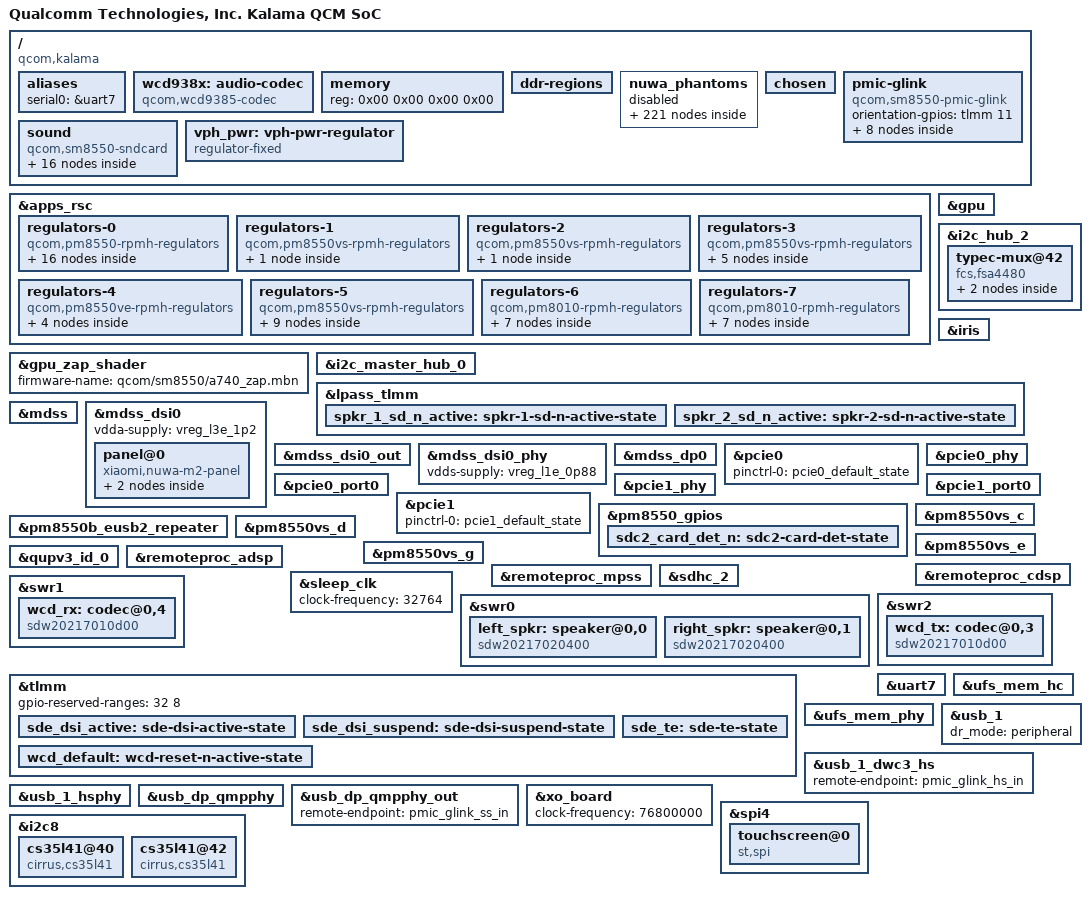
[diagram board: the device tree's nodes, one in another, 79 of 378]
// SPDX-License-Identifier: BSD-3-Clause
/*
 * Copyright (c) 2022, Linaro Limited
 */

/dts-v1/;

#include <dt-bindings/regulator/qcom,rpmh-regulator.h>
#include "sm8550.dtsi"
#include "pm8010.dtsi"
#include "pm8550.dtsi"
#include "pm8550b.dtsi"
#define PMK8550VE_SID 5
#include "pm8550ve.dtsi"
#include "pm8550vs.dtsi"
#include "pmk8550.dtsi"
#include "pmr735d_a.dtsi"
#include "pmr735d_b.dtsi"

/ {
	model = "Qualcomm Technologies, Inc. Kalama QCM SoC";
	compatible = "qcom,kalama";
	qcom,msm-id = <0x25c 0x20000>;
	qcom,board-id = <0x00 0x00>;
	chassis-type = "handset";

	aliases {
		serial0 = &uart7;
	};

	wcd938x: audio-codec {
		compatible = "qcom,wcd9385-codec";

		pinctrl-names = "default";
		pinctrl-0 = <&wcd_default>;

		qcom,micbias1-microvolt = <1800000>;
		qcom,micbias2-microvolt = <1800000>;
		qcom,micbias3-microvolt = <1800000>;
		qcom,micbias4-microvolt = <1800000>;
		qcom,mbhc-buttons-vthreshold-microvolt = <75000 150000 237000 500000 500000 500000 500000 500000>;
		qcom,mbhc-headset-vthreshold-microvolt = <1700000>;
		qcom,mbhc-headphone-vthreshold-microvolt = <50000>;
		qcom,rx-device = <&wcd_rx>;
		qcom,tx-device = <&wcd_tx>;

		reset-gpios = <&tlmm 108 GPIO_ACTIVE_LOW>;

		vdd-buck-supply = <&vreg_l15b_1p8>;
		vdd-rxtx-supply = <&vreg_l15b_1p8>;
		vdd-io-supply = <&vreg_l15b_1p8>;
		vdd-mic-bias-supply = <&vreg_bob1>;

		#sound-dai-cells = <1>;
	};

	memory {
		device_type = "memory";
		reg = <0x00 0x00 0x00 0x00>;
	};

	ddr-regions {
	};

		nuwa_phantoms {
		status = "disabled";
		APC1_pause: sym_APC1_pause { status = "disabled"; };
		APSS_OFF: sym_APSS_OFF { status = "disabled"; };
		BOB1: sym_BOB1 { status = "disabled"; };
		BOB2: sym_BOB2 { status = "disabled"; };
		CLUSTER_PWR_DN: sym_CLUSTER_PWR_DN { status = "disabled"; };
		GOLD_OFF: sym_GOLD_OFF { status = "disabled"; };
		L10B: sym_L10B { status = "disabled"; };
		L11B: sym_L11B { status = "disabled"; };
		L12B: sym_L12B { status = "disabled"; };
		L13B: sym_L13B { status = "disabled"; };
		L14B: sym_L14B { status = "disabled"; };
		L15B: sym_L15B { status = "disabled"; };
		L16B: sym_L16B { status = "disabled"; };
		L17B: sym_L17B { status = "disabled"; };
		L1B: sym_L1B { status = "disabled"; };
		L1C: sym_L1C { status = "disabled"; };
		L1D: sym_L1D { status = "disabled"; };
		L1E: sym_L1E { status = "disabled"; };
		L1F: sym_L1F { status = "disabled"; };
		L1G: sym_L1G { status = "disabled"; };
		L1K: sym_L1K { status = "disabled"; };
		L1M: sym_L1M { status = "disabled"; };
		L1N: sym_L1N { status = "disabled"; };
		L2B: sym_L2B { status = "disabled"; };
		L2C: sym_L2C { status = "disabled"; };
		L2D_LEVEL: sym_L2D_LEVEL { status = "disabled"; };
		L2E: sym_L2E { status = "disabled"; };
		L2F: sym_L2F { status = "disabled"; };
		L2G: sym_L2G { status = "disabled"; };
		L2K: sym_L2K { status = "disabled"; };
		L2M: sym_L2M { status = "disabled"; };
		L2N: sym_L2N { status = "disabled"; };
		L3C: sym_L3C { status = "disabled"; };
		L3E: sym_L3E { status = "disabled"; };
		L3F: sym_L3F { status = "disabled"; };
		L3G: sym_L3G { status = "disabled"; };
		L3K: sym_L3K { status = "disabled"; };
		L3L: sym_L3L { status = "disabled"; };
		L3M: sym_L3M { status = "disabled"; };
		L3N: sym_L3N { status = "disabled"; };
		L4K: sym_L4K { status = "disabled"; };
		L4L: sym_L4L { status = "disabled"; };
		L4M: sym_L4M { status = "disabled"; };
		L4N: sym_L4N { status = "disabled"; };
		L5B: sym_L5B { status = "disabled"; };
		L5K: sym_L5K { status = "disabled"; };
		L5L: sym_L5L { status = "disabled"; };
		L5M: sym_L5M { status = "disabled"; };
		L5N: sym_L5N { status = "disabled"; };
		L6B: sym_L6B { status = "disabled"; };
		L6K: sym_L6K { status = "disabled"; };
		L6L: sym_L6L { status = "disabled"; };
		L6M: sym_L6M { status = "disabled"; };
		L6N: sym_L6N { status = "disabled"; };
		L7B: sym_L7B { status = "disabled"; };
		L7K: sym_L7K { status = "disabled"; };
		L7L: sym_L7L { status = "disabled"; };
		L7M: sym_L7M { status = "disabled"; };
		L7N: sym_L7N { status = "disabled"; };
		L8B: sym_L8B { status = "disabled"; };
		L9B: sym_L9B { status = "disabled"; };
		S3G: sym_S3G { status = "disabled"; };
		S4G: sym_S4G { status = "disabled"; };
		S6G: sym_S6G { status = "disabled"; };
		SILVER_OFF: sym_SILVER_OFF { status = "disabled"; };
		VDD_MMCX_LEVEL: sym_VDD_MMCX_LEVEL { status = "disabled"; };
		VDD_MXA_LEVEL: sym_VDD_MXA_LEVEL { status = "disabled"; };
		altmode: sym_altmode { status = "disabled"; };
		ap2mdm_active: sym_ap2mdm_active { status = "disabled"; };
		ap2mdm_sleep: sym_ap2mdm_sleep { status = "disabled"; };
		apps_rsc_drv2: sym_apps_rsc_drv2 { status = "disabled"; };
		arch_timer: sym_arch_timer { status = "disabled"; };
		audio_gpr: sym_audio_gpr { status = "disabled"; };
		battery_charger: sym_battery_charger { status = "disabled"; };
		bwmon_ddr: sym_bwmon_ddr { status = "disabled"; };
		bwmon_llcc: sym_bwmon_llcc { status = "disabled"; };
		cam_cc_titan_top_gdsc: sym_cam_cc_titan_top_gdsc { status = "disabled"; };
		cam_cci0: sym_cam_cci0 { status = "disabled"; };
		cam_cci1: sym_cam_cci1 { status = "disabled"; };
		cam_cci2: sym_cam_cci2 { status = "disabled"; };
		cam_csiphy0: sym_cam_csiphy0 { status = "disabled"; };
		cam_csiphy1: sym_cam_csiphy1 { status = "disabled"; };
		cam_csiphy2: sym_cam_csiphy2 { status = "disabled"; };
		cam_csiphy3: sym_cam_csiphy3 { status = "disabled"; };
		cam_csiphy4: sym_cam_csiphy4 { status = "disabled"; };
		cam_csiphy5: sym_cam_csiphy5 { status = "disabled"; };
		cam_sensor_active_rst0: sym_cam_sensor_active_rst0 { status = "disabled"; };
		cam_sensor_active_rst1: sym_cam_sensor_active_rst1 { status = "disabled"; };
		cam_sensor_active_rst2: sym_cam_sensor_active_rst2 { status = "disabled"; };
		cam_sensor_active_rst3: sym_cam_sensor_active_rst3 { status = "disabled"; };
		cam_sensor_active_rst4: sym_cam_sensor_active_rst4 { status = "disabled"; };
		cam_sensor_active_rst5: sym_cam_sensor_active_rst5 { status = "disabled"; };
		cam_sensor_mclk0_active: sym_cam_sensor_mclk0_active { status = "disabled"; };
		cam_sensor_mclk0_suspend: sym_cam_sensor_mclk0_suspend { status = "disabled"; };
		cam_sensor_mclk1_active: sym_cam_sensor_mclk1_active { status = "disabled"; };
		cam_sensor_mclk1_suspend: sym_cam_sensor_mclk1_suspend { status = "disabled"; };
		cam_sensor_mclk2_active: sym_cam_sensor_mclk2_active { status = "disabled"; };
		cam_sensor_mclk2_suspend: sym_cam_sensor_mclk2_suspend { status = "disabled"; };
		cam_sensor_mclk3_active: sym_cam_sensor_mclk3_active { status = "disabled"; };
		cam_sensor_mclk3_suspend: sym_cam_sensor_mclk3_suspend { status = "disabled"; };
		cam_sensor_mclk4_active: sym_cam_sensor_mclk4_active { status = "disabled"; };
		cam_sensor_mclk4_suspend: sym_cam_sensor_mclk4_suspend { status = "disabled"; };
		cam_sensor_mclk5_active: sym_cam_sensor_mclk5_active { status = "disabled"; };
		cam_sensor_mclk5_suspend: sym_cam_sensor_mclk5_suspend { status = "disabled"; };
		cam_sensor_ponv_active: sym_cam_sensor_ponv_active { status = "disabled"; };
		cam_sensor_ponv_suspend: sym_cam_sensor_ponv_suspend { status = "disabled"; };
		cam_sensor_suspend_rst0: sym_cam_sensor_suspend_rst0 { status = "disabled"; };
		cam_sensor_suspend_rst1: sym_cam_sensor_suspend_rst1 { status = "disabled"; };
		cam_sensor_suspend_rst2: sym_cam_sensor_suspend_rst2 { status = "disabled"; };
		cam_sensor_suspend_rst3: sym_cam_sensor_suspend_rst3 { status = "disabled"; };
		cam_sensor_suspend_rst4: sym_cam_sensor_suspend_rst4 { status = "disabled"; };
		cam_sensor_suspend_rst5: sym_cam_sensor_suspend_rst5 { status = "disabled"; };
		cdsp_sw: sym_cdsp_sw { status = "disabled"; };
		chosen: sym_chosen { status = "disabled"; };
		cpu3_hotplug: sym_cpu3_hotplug { status = "disabled"; };
		cpu4_hotplug: sym_cpu4_hotplug { status = "disabled"; };
		cpu5_hotplug: sym_cpu5_hotplug { status = "disabled"; };
		cpu6_hotplug: sym_cpu6_hotplug { status = "disabled"; };
		cpu7_hotplug: sym_cpu7_hotplug { status = "disabled"; };
		cpu_3_4_5_pause: sym_cpu_3_4_5_pause { status = "disabled"; };
		cpu_6_7_pause: sym_cpu_6_7_pause { status = "disabled"; };
		disp_cc_mdss_core_gdsc: sym_disp_cc_mdss_core_gdsc { status = "disabled"; };
		disp_rsc_drv0: sym_disp_rsc_drv0 { status = "disabled"; };
		display_fps: sym_display_fps { status = "disabled"; };
		eusb2_phy0: sym_eusb2_phy0 { status = "disabled"; };
		fsa4480: sym_fsa4480 { status = "disabled"; };
		gcc_ufs_mem_phy_gdsc: sym_gcc_ufs_mem_phy_gdsc { status = "disabled"; };
		gcc_ufs_phy_gdsc: sym_gcc_ufs_phy_gdsc { status = "disabled"; };
		gcc_usb3_phy_gdsc: sym_gcc_usb3_phy_gdsc { status = "disabled"; };
		gpio_key_active: sym_gpio_key_active { status = "disabled"; };
		gpio_key_suspend: sym_gpio_key_suspend { status = "disabled"; };
		i2c_freq_1Mhz_cci2: sym_i2c_freq_1Mhz_cci2 { status = "disabled"; };
		i2c_freq_400Khz_cci1: sym_i2c_freq_400Khz_cci1 { status = "disabled"; };
		i2c_freq_custom_cci0: sym_i2c_freq_custom_cci0 { status = "disabled"; };
		i2c_freq_custom_cci1: sym_i2c_freq_custom_cci1 { status = "disabled"; };
		i2s1_sck_active: sym_i2s1_sck_active { status = "disabled"; };
		i2s1_sck_sleep: sym_i2s1_sck_sleep { status = "disabled"; };
		i2s1_sd0_active: sym_i2s1_sd0_active { status = "disabled"; };
		i2s1_sd0_sleep: sym_i2s1_sd0_sleep { status = "disabled"; };
		i2s1_ws_active: sym_i2s1_ws_active { status = "disabled"; };
		i2s1_ws_sleep: sym_i2s1_ws_sleep { status = "disabled"; };
		i3c0: sym_i3c0 { status = "disabled"; };
		lpass_audio_hw_vote: sym_lpass_audio_hw_vote { status = "disabled"; };
		lpass_cdc: sym_lpass_cdc { status = "disabled"; };
		lpass_core_hw_vote: sym_lpass_core_hw_vote { status = "disabled"; };
		lpi_tlmm: sym_lpi_tlmm { status = "disabled"; };
		mdm2ap_active: sym_mdm2ap_active { status = "disabled"; };
		mdm2ap_sleep: sym_mdm2ap_sleep { status = "disabled"; };
		memtimer: sym_memtimer { status = "disabled"; };
		modem_lte_dsc: sym_modem_lte_dsc { status = "disabled"; };
		modem_nr_dsc: sym_modem_nr_dsc { status = "disabled"; };
		modem_nr_scg_dsc: sym_modem_nr_scg_dsc { status = "disabled"; };
		modem_pas: sym_modem_pas { status = "disabled"; };
		msm_gpu: sym_msm_gpu { status = "disabled"; };
		nfc_enable_active: sym_nfc_enable_active { status = "disabled"; };
		nfc_enable_suspend: sym_nfc_enable_suspend { status = "disabled"; };
		nfc_int_active: sym_nfc_int_active { status = "disabled"; };
		nfc_int_suspend: sym_nfc_int_suspend { status = "disabled"; };
		pcie1_rp: sym_pcie1_rp { status = "disabled"; };
		pm_humu_l15: sym_pm_humu_l15 { status = "disabled"; };
		pm_humu_l17: sym_pm_humu_l17 { status = "disabled"; };
		pm_humu_l5: sym_pm_humu_l5 { status = "disabled"; };
		pm_humu_l8: sym_pm_humu_l8 { status = "disabled"; };
		pm_humu_l9: sym_pm_humu_l9 { status = "disabled"; };
		pm_v6d_l1: sym_pm_v6d_l1 { status = "disabled"; };
		pm_v6e_l1: sym_pm_v6e_l1 { status = "disabled"; };
		pm_v6e_l3: sym_pm_v6e_l3 { status = "disabled"; };
		pm_v6g_l1: sym_pm_v6g_l1 { status = "disabled"; };
		pm_v6g_l3: sym_pm_v6g_l3 { status = "disabled"; };
		pm_v6g_s4: sym_pm_v6g_s4 { status = "disabled"; };
		qcom_qbt: sym_qcom_qbt { status = "disabled"; };
		qseecom_mem: sym_qseecom_mem { status = "disabled"; };
		qseecom_ta_mem: sym_qseecom_ta_mem { status = "disabled"; };
		qupv3_2: sym_qupv3_2 { status = "disabled"; };
		qupv3_hub_i2c2: sym_qupv3_hub_i2c2 { status = "disabled"; };
		qupv3_hub_i2c3: sym_qupv3_hub_i2c3 { status = "disabled"; };
		qupv3_se0_i2c: sym_qupv3_se0_i2c { status = "disabled"; };
		qupv3_se10_i2c: sym_qupv3_se10_i2c { status = "disabled"; };
		qupv3_se11_i2c: sym_qupv3_se11_i2c { status = "disabled"; };
		qupv3_se1_i2c: sym_qupv3_se1_i2c { status = "disabled"; };
		qupv3_se4_i2c: sym_qupv3_se4_i2c { status = "disabled"; };
		qupv3_se4_spi: sym_qupv3_se4_spi { status = "disabled"; };
		qupv3_se4_spi_clk_active: sym_qupv3_se4_spi_clk_active { status = "disabled"; };
		qupv3_se4_spi_miso_active: sym_qupv3_se4_spi_miso_active { status = "disabled"; };
		qupv3_se4_spi_mosi_active: sym_qupv3_se4_spi_mosi_active { status = "disabled"; };
		qupv3_se5_i2c: sym_qupv3_se5_i2c { status = "disabled"; };
		qupv3_se8_i2c: sym_qupv3_se8_i2c { status = "disabled"; };
		qupv3_se8_spi: sym_qupv3_se8_spi { status = "disabled"; };
		qupv3_se8_spi_clk_active: sym_qupv3_se8_spi_clk_active { status = "disabled"; };
		qupv3_se8_spi_miso_active: sym_qupv3_se8_spi_miso_active { status = "disabled"; };
		qupv3_se8_spi_mosi_active: sym_qupv3_se8_spi_mosi_active { status = "disabled"; };
		qupv3_se9_i2c: sym_qupv3_se9_i2c { status = "disabled"; };
		qupv3_se9_spi: sym_qupv3_se9_spi { status = "disabled"; };
		sdc2_off: sym_sdc2_off { status = "disabled"; };
		sdc2_on: sym_sdc2_on { status = "disabled"; };
		smp2p_ipa_1_in: sym_smp2p_ipa_1_in { status = "disabled"; };
		smp2p_ipa_1_out: sym_smp2p_ipa_1_out { status = "disabled"; };
		spf_core_platform: sym_spf_core_platform { status = "disabled"; };
		stub_codec: sym_stub_codec { status = "disabled"; };
		tcsrcc: sym_tcsrcc { status = "disabled"; };
		tdm1_clk_active: sym_tdm1_clk_active { status = "disabled"; };
		tdm1_clk_sleep: sym_tdm1_clk_sleep { status = "disabled"; };
		tdm1_din_active: sym_tdm1_din_active { status = "disabled"; };
		tdm1_din_sleep: sym_tdm1_din_sleep { status = "disabled"; };
		tdm1_dout_active: sym_tdm1_dout_active { status = "disabled"; };
		tdm1_dout_sleep: sym_tdm1_dout_sleep { status = "disabled"; };
		tdm1_ws_active: sym_tdm1_ws_active { status = "disabled"; };
		tdm1_ws_sleep: sym_tdm1_ws_sleep { status = "disabled"; };
		thermal_zones: sym_thermal_zones { status = "disabled"; };
		ts_active: sym_ts_active { status = "disabled"; };
		ts_int_suspend: sym_ts_int_suspend { status = "disabled"; };
		ts_release: sym_ts_release { status = "disabled"; };
		ts_reset_suspend: sym_ts_reset_suspend { status = "disabled"; };
		ucsi: sym_ucsi { status = "disabled"; };
		ufshc_mem: sym_ufshc_mem { status = "disabled"; };
		ufsphy_mem: sym_ufsphy_mem { status = "disabled"; };
		usb0: sym_usb0 { status = "disabled"; };
		usb3phy_portselect_gpio: sym_usb3phy_portselect_gpio { status = "disabled"; };
		usb_qmp_dp_phy: sym_usb_qmp_dp_phy { status = "disabled"; };
		wcd938x_reset_active: sym_wcd938x_reset_active { status = "disabled"; };
		wcd938x_reset_sleep: sym_wcd938x_reset_sleep { status = "disabled"; };
	};

	chosen {
		stdout-path = "serial0:115200n8";
		bootargs = "console=ttyMSM0,115200n8 kpti=0 kernel.panic_on_rcu_stall=1 service_locator.enable=1 msm_rtb.filter=0x237 rcupdate.rcu_expedited=1 rcu_nocbs=0-7 ftrace_dump_on_oops swiotlb=noforce loop.max_part=7 fw_devlink.strict=1 allow_mismatched_32bit_el0 cpufreq.default_governor=performance printk.console_no_auto_verbose=0 kasan=off sysctl.kernel.sched_pelt_multiplier=4 can.stats_timer=0 pcie_ports=compat irqaffinity=0-2 disable_dma32=on no-steal-acc cgroup.memory=nokmem,nosocket";
	};

	pmic-glink {
		compatible = "qcom,sm8550-pmic-glink", "qcom,pmic-glink";
		#address-cells = <1>;
		#size-cells = <0>;
		orientation-gpios = <&tlmm 11 GPIO_ACTIVE_HIGH>;

		connector@0 {
			compatible = "usb-c-connector";
			reg = <0>;
			power-role = "dual";
			data-role = "dual";

			ports {
				#address-cells = <1>;
				#size-cells = <0>;

				port@0 {
					reg = <0>;

					pmic_glink_hs_in: endpoint {
						remote-endpoint = <&usb_1_dwc3_hs>;
					};
				};

				port@1 {
					reg = <1>;

					pmic_glink_ss_in: endpoint {
						remote-endpoint = <&usb_dp_qmpphy_out>;
					};
				};

				port@2 {
					reg = <2>;

					pmic_glink_sbu: endpoint {
						remote-endpoint = <&fsa4480_sbu_mux>;
					};
				};
			};
		};
	};

	sound {
		compatible = "qcom,sm8550-sndcard", "qcom,sm8450-sndcard";
		model = "SM8550-MTP";
		audio-routing = "SpkrLeft IN", "WSA_SPK1 OUT",
				"SpkrRight IN", "WSA_SPK2 OUT",
				"IN1_HPHL", "HPHL_OUT",
				"IN2_HPHR", "HPHR_OUT",
				"AMIC1", "MIC BIAS1",
				"AMIC2", "MIC BIAS2",
				"AMIC3", "MIC BIAS3",
				"AMIC4", "MIC BIAS3",
				"AMIC5", "MIC BIAS4",
				"VA DMIC0", "MIC BIAS1",
				"VA DMIC1", "MIC BIAS1",
				"VA DMIC2", "MIC BIAS3",
				"TX DMIC0", "MIC BIAS1",
				"TX DMIC1", "MIC BIAS2",
				"TX DMIC2", "MIC BIAS3",
				"TX SWR_INPUT0", "ADC1_OUTPUT",
				"TX SWR_INPUT1", "ADC2_OUTPUT",
				"TX SWR_INPUT0", "ADC3_OUTPUT",
				"TX SWR_INPUT1", "ADC4_OUTPUT";

		wcd-playback-dai-link {
			link-name = "WCD Playback";

			cpu {
				sound-dai = <&q6apmbedai RX_CODEC_DMA_RX_0>;
			};

			codec {
				sound-dai = <&wcd938x 0>, <&swr1 0>, <&lpass_rxmacro 0>;
			};

			platform {
				sound-dai = <&q6apm>;
			};
		};

		wcd-capture-dai-link {
			link-name = "WCD Capture";

			cpu {
				sound-dai = <&q6apmbedai TX_CODEC_DMA_TX_3>;
			};

			codec {
				sound-dai = <&wcd938x 1>, <&swr2 0>, <&lpass_txmacro 0>;
			};

			platform {
				sound-dai = <&q6apm>;
			};
		};

		wsa-dai-link {
			link-name = "WSA Playback";

			cpu {
				sound-dai = <&q6apmbedai WSA_CODEC_DMA_RX_0>;
			};

			codec {
				sound-dai = <&left_spkr>, <&right_spkr>, <&swr0 0>, <&lpass_wsamacro 0>;
			};

			platform {
				sound-dai = <&q6apm>;
			};
		};

		va-dai-link {
			link-name = "VA Capture";

			cpu {
				sound-dai = <&q6apmbedai TX_CODEC_DMA_TX_3>;
			};

			codec {
				sound-dai = <&lpass_vamacro 0>;
			};

			platform {
				sound-dai = <&q6apm>;
			};
		};
	};

	vph_pwr: vph-pwr-regulator {
		compatible = "regulator-fixed";
		regulator-name = "vph_pwr";
		regulator-min-microvolt = <3700000>;
		regulator-max-microvolt = <3700000>;

		regulator-always-on;
		regulator-boot-on;
	};
};

&apps_rsc {
	regulators-0 {
		compatible = "qcom,pm8550-rpmh-regulators";
		qcom,pmic-id = "b";

		vdd-bob1-supply = <&vph_pwr>;
		vdd-bob2-supply = <&vph_pwr>;
		vdd-l1-l4-l10-supply = <&vreg_s6g_1p8>;
		vdd-l2-l13-l14-supply = <&vreg_bob1>;
		vdd-l3-supply = <&vreg_s4g_1p3>;
		vdd-l5-l16-supply = <&vreg_bob1>;
		vdd-l6-l7-supply = <&vreg_bob1>;
		vdd-l8-l9-supply = <&vreg_bob1>;
		vdd-l11-supply = <&vreg_s4g_1p3>;
		vdd-l12-supply = <&vreg_s6g_1p8>;
		vdd-l15-supply = <&vreg_s6g_1p8>;
		vdd-l17-supply = <&vreg_bob2>;

		vreg_bob1: bob1 {
			regulator-name = "vreg_bob1";
			regulator-min-microvolt = <3296000>;
			regulator-max-microvolt = <3960000>;
			regulator-initial-mode = <RPMH_REGULATOR_MODE_HPM>;
		};

		vreg_bob2: bob2 {
			regulator-name = "vreg_bob2";
			regulator-min-microvolt = <2720000>;
			regulator-max-microvolt = <3960000>;
			regulator-initial-mode = <RPMH_REGULATOR_MODE_HPM>;
		};

		vreg_l1b_1p8: ldo1 {
			regulator-name = "vreg_l1b_1p8";
			regulator-min-microvolt = <1800000>;
			regulator-max-microvolt = <1800000>;
			regulator-initial-mode = <RPMH_REGULATOR_MODE_HPM>;
		};

		vreg_l2b_3p0: ldo2 {
			regulator-name = "vreg_l2b_3p0";
			regulator-min-microvolt = <3008000>;
			regulator-max-microvolt = <3008000>;
			regulator-initial-mode = <RPMH_REGULATOR_MODE_HPM>;
		};

		vreg_l5b_3p1: ldo5 {
			regulator-name = "vreg_l5b_3p1";
			regulator-min-microvolt = <3104000>;
			regulator-max-microvolt = <3104000>;
			regulator-initial-mode = <RPMH_REGULATOR_MODE_HPM>;
		};

		vreg_l6b_1p8: ldo6 {
			regulator-name = "vreg_l6b_1p8";
			regulator-min-microvolt = <1800000>;
			regulator-max-microvolt = <3008000>;
			regulator-initial-mode = <RPMH_REGULATOR_MODE_HPM>;
		};

		vreg_l7b_1p8: ldo7 {
			regulator-name = "vreg_l7b_1p8";
			regulator-min-microvolt = <1800000>;
			regulator-max-microvolt = <3008000>;
			regulator-initial-mode = <RPMH_REGULATOR_MODE_HPM>;
		};

		vreg_l8b_1p8: ldo8 {
			regulator-name = "vreg_l8b_1p8";
			regulator-min-microvolt = <1800000>;
			regulator-max-microvolt = <3008000>;
			regulator-initial-mode = <RPMH_REGULATOR_MODE_HPM>;
		};

		vreg_l9b_2p9: ldo9 {
			regulator-name = "vreg_l9b_2p9";
			regulator-min-microvolt = <2960000>;
			regulator-max-microvolt = <3008000>;
			regulator-initial-mode = <RPMH_REGULATOR_MODE_HPM>;
		};

		vreg_l11b_1p2: ldo11 {
			regulator-name = "vreg_l11b_1p2";
			regulator-min-microvolt = <1200000>;
			regulator-max-microvolt = <1504000>;
			regulator-initial-mode = <RPMH_REGULATOR_MODE_HPM>;
		};

		vreg_l12b_1p8: ldo12 {
			regulator-name = "vreg_l12b_1p8";
			regulator-min-microvolt = <1800000>;
			regulator-max-microvolt = <1800000>;
			regulator-initial-mode = <RPMH_REGULATOR_MODE_HPM>;
		};

		vreg_l13b_3p0: ldo13 {
			regulator-name = "vreg_l13b_3p0";
			regulator-min-microvolt = <3000000>;
			regulator-max-microvolt = <3000000>;
			regulator-initial-mode = <RPMH_REGULATOR_MODE_HPM>;
		};

		vreg_l14b_3p2: ldo14 {
			regulator-name = "vreg_l14b_3p2";
			regulator-min-microvolt = <3200000>;
			regulator-max-microvolt = <3200000>;
			regulator-initial-mode = <RPMH_REGULATOR_MODE_HPM>;
		};

		vreg_l15b_1p8: ldo15 {
			regulator-name = "vreg_l15b_1p8";
			regulator-min-microvolt = <1800000>;
			regulator-max-microvolt = <1800000>;
			regulator-initial-mode = <RPMH_REGULATOR_MODE_HPM>;
		};

		vreg_l16b_2p8: ldo16 {
			regulator-name = "vreg_l16b_2p8";
			regulator-min-microvolt = <2800000>;
			regulator-max-microvolt = <2800000>;
			regulator-initial-mode = <RPMH_REGULATOR_MODE_HPM>;
		};

		vreg_l17b_2p5: ldo17 {
			regulator-name = "vreg_l17b_2p5";
			regulator-min-microvolt = <2504000>;
			regulator-max-microvolt = <2504000>;
			regulator-initial-mode = <RPMH_REGULATOR_MODE_HPM>;
		};
	};

	regulators-1 {
		compatible = "qcom,pm8550vs-rpmh-regulators";
		qcom,pmic-id = "c";

		vdd-l3-supply = <&vreg_s4e_0p9>;

		vreg_l3c_0p91: ldo3 {
			regulator-name = "vreg_l3c_0p9";
			regulator-min-microvolt = <880000>;
			regulator-max-microvolt = <912000>;
			regulator-initial-mode = <RPMH_REGULATOR_MODE_HPM>;
		};
	};

	regulators-2 {
		compatible = "qcom,pm8550vs-rpmh-regulators";
		qcom,pmic-id = "d";

		vdd-l1-supply = <&vreg_s4e_0p9>;

		vreg_l1d_0p88: ldo1 {
			regulator-name = "vreg_l1d_0p88";
			regulator-min-microvolt = <880000>;
			regulator-max-microvolt = <920000>;
			regulator-initial-mode = <RPMH_REGULATOR_MODE_HPM>;
		};
	};

	regulators-3 {
		compatible = "qcom,pm8550vs-rpmh-regulators";
		qcom,pmic-id = "e";

		vdd-l1-supply = <&vreg_s4e_0p9>;
		vdd-l2-supply = <&vreg_s4e_0p9>;
		vdd-l3-supply = <&vreg_s4g_1p3>;
		vdd-s4-supply = <&vph_pwr>;
		vdd-s5-supply = <&vph_pwr>;

		vreg_s4e_0p9: smps4 {
			regulator-name = "vreg_s4e_0p9";
			regulator-min-microvolt = <904000>;
			regulator-max-microvolt = <984000>;
			regulator-initial-mode = <RPMH_REGULATOR_MODE_HPM>;
		};

		vreg_s5e_1p1: smps5 {
			regulator-name = "vreg_s5e_1p1";
			regulator-min-microvolt = <1080000>;
			regulator-max-microvolt = <1120000>;
			regulator-initial-mode = <RPMH_REGULATOR_MODE_HPM>;
		};

		vreg_l1e_0p88: ldo1 {
			regulator-name = "vreg_l1e_0p88";
			regulator-min-microvolt = <880000>;
			regulator-max-microvolt = <880000>;
			regulator-initial-mode = <RPMH_REGULATOR_MODE_HPM>;
		};

		vreg_l2e_0p9: ldo2 {
			regulator-name = "vreg_l2e_0p9";
			regulator-min-microvolt = <904000>;
			regulator-max-microvolt = <970000>;
			regulator-initial-mode = <RPMH_REGULATOR_MODE_HPM>;
		};

		vreg_l3e_1p2: ldo3 {
			regulator-name = "vreg_l3e_1p2";
			regulator-min-microvolt = <1200000>;
			regulator-max-microvolt = <1200000>;
			regulator-initial-mode = <RPMH_REGULATOR_MODE_HPM>;
		};
	};

	regulators-4 {
		compatible = "qcom,pm8550ve-rpmh-regulators";
		qcom,pmic-id = "f";

		vdd-l1-supply = <&vreg_s4e_0p9>;
		vdd-l2-supply = <&vreg_s4e_0p9>;
		vdd-l3-supply = <&vreg_s4e_0p9>;
		vdd-s4-supply = <&vph_pwr>;

		vreg_s4f_0p5: smps4 {
			regulator-name = "vreg_s4f_0p5";
			regulator-min-microvolt = <500000>;
			regulator-max-microvolt = <700000>;
			regulator-initial-mode = <RPMH_REGULATOR_MODE_HPM>;
		};

		vreg_l1f_0p9: ldo1 {
			regulator-name = "vreg_l1f_0p9";
			regulator-min-microvolt = <912000>;
			regulator-max-microvolt = <912000>;
			regulator-initial-mode = <RPMH_REGULATOR_MODE_HPM>;
		};

		vreg_l2f_0p88: ldo2 {
			regulator-name = "vreg_l2f_0p88";
			regulator-min-microvolt = <880000>;
			regulator-max-microvolt = <912000>;
			regulator-initial-mode = <RPMH_REGULATOR_MODE_HPM>;
		};

		vreg_l3f_0p91: ldo3 {
			regulator-name = "vreg_l3f_0p91";
			regulator-min-microvolt = <880000>;
			regulator-max-microvolt = <912000>;
			regulator-initial-mode = <RPMH_REGULATOR_MODE_HPM>;
		};
	};

	regulators-5 {
		compatible = "qcom,pm8550vs-rpmh-regulators";
		qcom,pmic-id = "g";

		vdd-l1-supply = <&vreg_s4g_1p3>;
		vdd-l2-supply = <&vreg_s4g_1p3>;
		vdd-l3-supply = <&vreg_s4g_1p3>;
		vdd-s1-supply = <&vph_pwr>;
		vdd-s2-supply = <&vph_pwr>;
		vdd-s3-supply = <&vph_pwr>;
		vdd-s4-supply = <&vph_pwr>;
		vdd-s5-supply = <&vph_pwr>;
		vdd-s6-supply = <&vph_pwr>;

		vreg_s1g_1p2: smps1 {
			regulator-name = "vreg_s1g_1p2";
			regulator-min-microvolt = <1200000>;
			regulator-max-microvolt = <1300000>;
			regulator-initial-mode = <RPMH_REGULATOR_MODE_HPM>;
		};

		vreg_s2g_0p8: smps2 {
			regulator-name = "vreg_s2g_0p8";
			regulator-min-microvolt = <800000>;
			regulator-max-microvolt = <1000000>;
			regulator-initial-mode = <RPMH_REGULATOR_MODE_HPM>;
		};

		vreg_s3g_0p7: smps3 {
			regulator-name = "vreg_s3g_0p7";
			regulator-min-microvolt = <300000>;
			regulator-max-microvolt = <1004000>;
			regulator-initial-mode = <RPMH_REGULATOR_MODE_HPM>;
		};

		vreg_s4g_1p3: smps4 {
			regulator-name = "vreg_s4g_1p3";
			regulator-min-microvolt = <1200000>;
			regulator-max-microvolt = <1352000>;
			regulator-initial-mode = <RPMH_REGULATOR_MODE_HPM>;
		};

		vreg_s5g_0p8: smps5 {
			regulator-name = "vreg_s5g_0p8";
			regulator-min-microvolt = <500000>;
			regulator-max-microvolt = <1004000>;
			regulator-initial-mode = <RPMH_REGULATOR_MODE_HPM>;
		};

		vreg_s6g_1p8: smps6 {
			regulator-name = "vreg_s6g_1p8";
			regulator-min-microvolt = <1800000>;
			regulator-max-microvolt = <2000000>;
			regulator-initial-mode = <RPMH_REGULATOR_MODE_HPM>;
		};

		vreg_l1g_1p2: ldo1 {
			regulator-name = "vreg_l1g_1p2";
			regulator-min-microvolt = <1200000>;
			regulator-max-microvolt = <1200000>;
			regulator-initial-mode = <RPMH_REGULATOR_MODE_HPM>;
		};

		vreg_l2g_1p2: ldo2 {
			regulator-name = "vreg_l2g_1p2";
			regulator-min-microvolt = <1200000>;
			regulator-max-microvolt = <1200000>;
			regulator-initial-mode = <RPMH_REGULATOR_MODE_HPM>;
		};

		vreg_l3g_1p2: ldo3 {
			regulator-name = "vreg_l3g_1p2";
			regulator-min-microvolt = <1200000>;
			regulator-max-microvolt = <1200000>;
			regulator-initial-mode = <RPMH_REGULATOR_MODE_HPM>;
		};
	};

	regulators-6 {
		compatible = "qcom,pm8010-rpmh-regulators";
		qcom,pmic-id = "m";

		vdd-l1-l2-supply = <&vreg_s4g_1p3>;
		vdd-l3-l4-supply = <&vreg_bob2>;
		vdd-l5-supply = <&vreg_s6g_1p8>;
		vdd-l6-supply = <&vreg_s6g_1p8>;
		vdd-l7-supply = <&vreg_bob1>;

		vreg_l1m_1p056: ldo1 {
			regulator-name = "vreg_l1m_1p056";
			regulator-min-microvolt = <1056000>;
			regulator-max-microvolt = <1056000>;
			regulator-initial-mode = <RPMH_REGULATOR_MODE_HPM>;
		};

		vreg_l2m_1p056: ldo2 {
			regulator-name = "vreg_l2m_1p056";
			regulator-min-microvolt = <1056000>;
			regulator-max-microvolt = <1056000>;
			regulator-initial-mode = <RPMH_REGULATOR_MODE_HPM>;
		};

		vreg_l3m_2p8: ldo3 {
			regulator-name = "vreg_l3m_2p8";
			regulator-min-microvolt = <2800000>;
			regulator-max-microvolt = <2800000>;
			regulator-initial-mode = <RPMH_REGULATOR_MODE_HPM>;
		};

		vreg_l4m_2p8: ldo4 {
			regulator-name = "vreg_l4m_2p8";
			regulator-min-microvolt = <2800000>;
			regulator-max-microvolt = <2800000>;
			regulator-initial-mode = <RPMH_REGULATOR_MODE_HPM>;
		};

		vreg_l5m_1p8: ldo5 {
			regulator-name = "vreg_l5m_1p8";
			regulator-min-microvolt = <1800000>;
			regulator-max-microvolt = <1800000>;
			regulator-initial-mode = <RPMH_REGULATOR_MODE_HPM>;
		};

		vreg_l6m_1p8: ldo6 {
			regulator-name = "vreg_l6m_1p8";
			regulator-min-microvolt = <1800000>;
			regulator-max-microvolt = <1800000>;
			regulator-initial-mode = <RPMH_REGULATOR_MODE_HPM>;
		};

		vreg_l7m_2p9: ldo7 {
			regulator-name = "vreg_l7m_2p9";
			regulator-min-microvolt = <2800000>;
			regulator-max-microvolt = <2904000>;
			regulator-initial-mode = <RPMH_REGULATOR_MODE_HPM>;
		};
	};

	regulators-7 {
		compatible = "qcom,pm8010-rpmh-regulators";
		qcom,pmic-id = "n";

		vdd-l1-l2-supply = <&vreg_s4g_1p3>;
		vdd-l3-l4-supply = <&vreg_bob2>;
		vdd-l5-supply = <&vreg_s6g_1p8>;
		vdd-l6-supply = <&vreg_bob1>;
		vdd-l7-supply = <&vreg_bob1>;

		vreg_l1n_1p1: ldo1 {
			regulator-name = "vreg_l1n_1p1";
			regulator-min-microvolt = <1104000>;
			regulator-max-microvolt = <1200000>;
			regulator-initial-mode = <RPMH_REGULATOR_MODE_HPM>;
		};

		vreg_l2n_1p1: ldo2 {
			regulator-name = "vreg_l2n_1p1";
			regulator-min-microvolt = <1104000>;
			regulator-max-microvolt = <1200000>;
			regulator-initial-mode = <RPMH_REGULATOR_MODE_HPM>;
		};

		vreg_l3n_2p8: ldo3 {
			regulator-name = "vreg_l3n_2p8";
			regulator-min-microvolt = <2800000>;
			regulator-max-microvolt = <3000000>;
			regulator-initial-mode = <RPMH_REGULATOR_MODE_HPM>;
		};

		vreg_l4n_2p8: ldo4 {
			regulator-name = "vreg_l4n_2p8";
			regulator-min-microvolt = <2800000>;
			regulator-max-microvolt = <3300000>;
			regulator-initial-mode = <RPMH_REGULATOR_MODE_HPM>;
		};

		vreg_l5n_1p8: ldo5 {
			regulator-name = "vreg_l5n_1p8";
			regulator-min-microvolt = <1800000>;
			regulator-max-microvolt = <1800000>;
			regulator-initial-mode = <RPMH_REGULATOR_MODE_HPM>;
		};

		vreg_l6n_3p3: ldo6 {
			regulator-name = "vreg_l6n_3p3";
			regulator-min-microvolt = <3200000>;
			regulator-max-microvolt = <3200000>;
			regulator-initial-mode = <RPMH_REGULATOR_MODE_HPM>;
		};

		vreg_l7n_2p96: ldo7 {
			regulator-name = "vreg_l7n_2p96";
			regulator-min-microvolt = <2800000>;
			regulator-max-microvolt = <2960000>;
			regulator-initial-mode = <RPMH_REGULATOR_MODE_HPM>;
		};
	};
};

&gpu {
	status = "okay";
};

&gpu_zap_shader {
	firmware-name = "qcom/sm8550/a740_zap.mbn";
};

&i2c_master_hub_0 {
	status = "okay";
};

&i2c_hub_2 {
	status = "okay";

	typec-mux@42 {
		compatible = "fcs,fsa4480";
		reg = <0x42>;

		vcc-supply = <&vreg_bob1>;

		mode-switch;
		orientation-switch;

		port {
			fsa4480_sbu_mux: endpoint {
				remote-endpoint = <&pmic_glink_sbu>;
			};
		};
	};
};

&iris {
	status = "okay";
};

&lpass_tlmm {
	spkr_1_sd_n_active: spkr-1-sd-n-active-state {
		pins = "gpio17";
		function = "gpio";
		drive-strength = <16>;
		bias-disable;
		output-low;
	};

	spkr_2_sd_n_active: spkr-2-sd-n-active-state {
		pins = "gpio18";
		function = "gpio";
		drive-strength = <16>;
		bias-disable;
		output-low;
	};
};

&mdss {
	status = "okay";
};

&mdss_dsi0 {
	vdda-supply = <&vreg_l3e_1p2>;
	status = "okay";

	panel@0 {
		compatible = "xiaomi,nuwa-m2-panel";
		reg = <0>;

		pinctrl-names = "default", "sleep";
		pinctrl-0 = <&sde_dsi_active>, <&sde_te>;
		pinctrl-1 = <&sde_dsi_suspend>, <&sde_te>;

		vddio-supply = <&vreg_l12b_1p8>;
		vci-supply = <&vreg_l13b_3p0>;
		vdd-supply = <&vreg_l11b_1p2>;

		reset-gpios = <&tlmm 133 GPIO_ACTIVE_LOW>;

		port {
			panel0_in: endpoint {
				remote-endpoint = <&mdss_dsi0_out>;
			};
		};
	};
};

&mdss_dsi0_out {
	remote-endpoint = <&panel0_in>;
	data-lanes = <0 1 2 3>;
};

&mdss_dsi0_phy {
	vdds-supply = <&vreg_l1e_0p88>;
	status = "okay";
};

&mdss_dp0 {
	status = "okay";
};

&pcie0 {
	pinctrl-names = "default";
	pinctrl-0 = <&pcie0_default_state>;

	status = "okay";
};

&pcie0_phy {
	vdda-phy-supply = <&vreg_l1e_0p88>;
	vdda-pll-supply = <&vreg_l3e_1p2>;

	status = "okay";
};

&pcie0_port0 {
	reset-gpios = <&tlmm 94 GPIO_ACTIVE_LOW>;
	wake-gpios = <&tlmm 96 GPIO_ACTIVE_LOW>;
};

&pcie1 {
	pinctrl-names = "default";
	pinctrl-0 = <&pcie1_default_state>;

	status = "okay";
};

&pcie1_phy {
	vdda-phy-supply = <&vreg_l3c_0p91>;
	vdda-pll-supply = <&vreg_l3e_1p2>;
	vdda-qref-supply = <&vreg_l1e_0p88>;

	status = "okay";
};

&pcie1_port0 {
	reset-gpios = <&tlmm 97 GPIO_ACTIVE_LOW>;
	wake-gpios = <&tlmm 99 GPIO_ACTIVE_LOW>;
};

&pm8550_gpios {
	sdc2_card_det_n: sdc2-card-det-state {
		pins = "gpio12";
		function = "normal";
		input-enable;
		output-disable;
		bias-pull-up;
		power-source = <1>; /* 1.8 V */
	};
};

&pm8550b_eusb2_repeater {
	vdd18-supply = <&vreg_l15b_1p8>;
	vdd3-supply = <&vreg_l5b_3p1>;
};

&pm8550vs_c {
	status = "okay";
};

&pm8550vs_d {
	status = "okay";
};

&pm8550vs_e {
	status = "okay";
};

&pm8550vs_g {
	status = "okay";
};

&qupv3_id_0 {
	status = "okay";
};

&remoteproc_adsp {
	firmware-name = "qcom/sm8550/adsp.mbn",
			"qcom/sm8550/adsp_dtb.mbn";
	status = "okay";
};

&remoteproc_cdsp {
	firmware-name = "qcom/sm8550/cdsp.mbn",
			"qcom/sm8550/cdsp_dtb.mbn";
	status = "okay";
};

&remoteproc_mpss {
	firmware-name = "qcom/sm8550/modem.mbn",
			"qcom/sm8550/modem_dtb.mbn";
	status = "okay";
};

&sdhc_2 {
	cd-gpios = <&pm8550_gpios 12 GPIO_ACTIVE_LOW>;
	pinctrl-names = "default", "sleep";
	pinctrl-0 = <&sdc2_default &sdc2_card_det_n>;
	pinctrl-1 = <&sdc2_sleep &sdc2_card_det_n>;
	vmmc-supply = <&vreg_l9b_2p9>;
	vqmmc-supply = <&vreg_l8b_1p8>;
	bus-width = <4>;
	no-sdio;
	no-mmc;
	status = "okay";
};

&sleep_clk {
	clock-frequency = <32764>;
};

&swr0 {
	status = "okay";

	/* WSA8845 */
	left_spkr: speaker@0,0 {
		compatible = "sdw20217020400";
		reg = <0 0>;
		pinctrl-names = "default";
		pinctrl-0 = <&spkr_1_sd_n_active>;
		powerdown-gpios = <&lpass_tlmm 17 GPIO_ACTIVE_LOW>;
		#sound-dai-cells = <0>;
		sound-name-prefix = "SpkrLeft";
		vdd-1p8-supply = <&vreg_l15b_1p8>;
		vdd-io-supply = <&vreg_l3g_1p2>;
		qcom,port-mapping = <1 2 3 7 10 13>;
	};

	/* WSA8845 */
	right_spkr: speaker@0,1 {
		compatible = "sdw20217020400";
		reg = <0 1>;
		pinctrl-names = "default";
		pinctrl-0 = <&spkr_2_sd_n_active>;
		powerdown-gpios = <&lpass_tlmm 18 GPIO_ACTIVE_LOW>;
		#sound-dai-cells = <0>;
		sound-name-prefix = "SpkrRight";
		vdd-1p8-supply = <&vreg_l15b_1p8>;
		vdd-io-supply = <&vreg_l3g_1p2>;
		qcom,port-mapping = <4 5 6 7 11 13>;
	};
};

&swr1 {
	status = "okay";

	/* WCD9385 RX */
	wcd_rx: codec@0,4 {
		compatible = "sdw20217010d00";
		reg = <0 4>;
		qcom,rx-port-mapping = <1 2 3 4 5>;
	};
};

&swr2 {
	status = "okay";

	/* WCD9385 TX */
	wcd_tx: codec@0,3 {
		compatible = "sdw20217010d00";
		reg = <0 3>;
		qcom,tx-port-mapping = <2 2 3 4>;
	};
};

&tlmm {
	gpio-reserved-ranges = <32 8>;

	sde_dsi_active: sde-dsi-active-state {
		pins = "gpio133";
		function = "gpio";
		drive-strength = <8>;
		bias-disable;
	};

	sde_dsi_suspend: sde-dsi-suspend-state {
		pins = "gpio133";
		function = "gpio";
		drive-strength = <2>;
		bias-pull-down;
	};

	sde_te: sde-te-state {
		pins = "gpio86";
		function = "mdp_vsync";
		drive-strength = <2>;
		bias-pull-down;
	};

	wcd_default: wcd-reset-n-active-state {
		pins = "gpio108";
		function = "gpio";
		drive-strength = <16>;
		bias-disable;
		output-low;
	};
};

&uart7 {
	status = "okay";
};

&ufs_mem_hc {
	reset-gpios = <&tlmm 210 GPIO_ACTIVE_LOW>;
	vcc-supply = <&vreg_l17b_2p5>;
	vcc-max-microamp = <1300000>;
	vccq-supply = <&vreg_l1g_1p2>;
	vccq-max-microamp = <1200000>;
	vdd-hba-supply = <&vreg_l3g_1p2>;

	status = "okay";
};

&ufs_mem_phy {
	vdda-phy-supply = <&vreg_l1d_0p88>;
	vdda-pll-supply = <&vreg_l3e_1p2>;

	status = "okay";
};

&usb_1 {
	status = "okay";
	dr_mode = "peripheral";
};

&usb_1_dwc3_hs {
	remote-endpoint = <&pmic_glink_hs_in>;
};

&usb_1_hsphy {
	vdd-supply = <&vreg_l1e_0p88>;
	vdda12-supply = <&vreg_l3e_1p2>;

	phys = <&pm8550b_eusb2_repeater>;

	status = "okay";
};

&usb_dp_qmpphy {
	vdda-phy-supply = <&vreg_l3f_0p91>;
	vdda-pll-supply = <&vreg_l3e_1p2>;

	status = "okay";
};

&usb_dp_qmpphy_out {
	remote-endpoint = <&pmic_glink_ss_in>;
};

&xo_board {
	clock-frequency = <76800000>;
};

&spi4 {
	status = "okay";

	touchscreen@0 {
		compatible = "st,spi";
		reg = <0>;
		interrupt-parent = <&tlmm>;
		interrupts = <25 IRQ_TYPE_EDGE_FALLING>;
		spi-max-frequency = <10000000>;

		fts,x-max = <14400>;
		fts,y-max = <32000>;
		fts,irq-gpio = <&tlmm 25 0x2008>;
		fts,reset-gpio = <&tlmm 24 0x00>;
		reset-gpios = <&tlmm 24 GPIO_ACTIVE_LOW>;

		status = "okay";
	};
};

&i2c8 {
	status = "okay";

	cs35l41@40 {
		compatible = "cirrus,cs35l41";
		reg = <0x40>;
		interrupt-parent = <&tlmm>;
		interrupts = <99 IRQ_TYPE_EDGE_FALLING>;
		reset-gpios = <&tlmm 183 GPIO_ACTIVE_LOW>;

		cirrus,fast-switch = "B-music.txt", "B-handfree.txt";
		sound-name-prefix = "B";
		cirrus,right-channel-amp;
		cirrus,asp-sdout-hiz = <0x03>;
		cirrus,boost-cap-microfarad = <0x0f>;
		cirrus,boost-ind-nanohenry = <0x3e8>;
		cirrus,boost-peak-milliamp = <0xfa0>;
		cirrus,temp-warn_threshold = <0x03>;

		status = "okay";
	};

	cs35l41@42 {
		compatible = "cirrus,cs35l41";
		reg = <0x42>;
		interrupt-parent = <&tlmm>;
		interrupts = <98 IRQ_TYPE_EDGE_FALLING>;
		reset-gpios = <&tlmm 182 GPIO_ACTIVE_LOW>;

		cirrus,fast-switch = "T-music.txt", "T-handset.txt", "T-handfree.txt";
		sound-name-prefix = "T";
		cirrus,asp-sdout-hiz = <0x03>;
		cirrus,boost-cap-microfarad = <0x0f>;
		cirrus,boost-ind-nanohenry = <0x3e8>;
		cirrus,boost-peak-milliamp = <0xfa0>;
		cirrus,temp-warn_threshold = <0x03>;

		status = "okay";
	};
};
